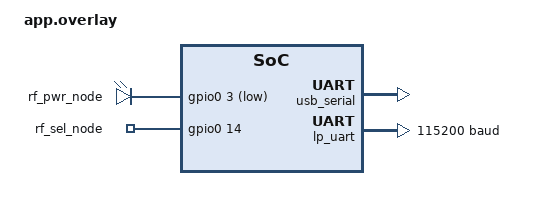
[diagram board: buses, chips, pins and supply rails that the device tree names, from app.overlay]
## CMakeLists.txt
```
# Copyright (c) 2025 Espressif Systems (Shanghai) Co., Ltd.
# SPDX-License-Identifier: Apache-2.0

cmake_minimum_required(VERSION 3.20.0)

list(APPEND EXTRA_CONF_FILE "${CMAKE_CURRENT_SOURCE_DIR}/lp_hp_shared.conf")

set(REMOTE_ZEPHYR_DIR ${CMAKE_CURRENT_BINARY_DIR}/../low_power_sensor_lpcore/zephyr)
set(LP_FULL_BIN ${CMAKE_BINARY_DIR}/../low_power_sensor_lpcore/zephyr/zephyr.bin)
set(LP_STRIPPED_BIN ${CMAKE_BINARY_DIR}/../low_power_sensor_lpcore/zephyr/zephyr_stripped.bin)

# Tell Zephyr to look in this app's directory for snippets
list(APPEND SNIPPET_ROOT ${CMAKE_CURRENT_SOURCE_DIR})

find_package(Zephyr REQUIRED HINTS $ENV{ZEPHYR_BASE})
message(STATUS "${CONFIG_BOARD_TARGET} compile as Master in this sample")
project(low_power_sensor_hpcore)

if(CONFIG_LPS_EXPLICIT_LP_IMAGE_LOADING)
    # This creates a recipe to produce 'zephyr_stripped.bin'
    add_custom_command(
        OUTPUT ${LP_STRIPPED_BIN}
        COMMAND head -c 8192 ${LP_FULL_BIN} > ${LP_STRIPPED_BIN}
        DEPENDS ${LP_FULL_BIN}
        COMMENT ">>> HP BUILD: Stripping LP binary to 8KB <<<"
    )

    # Create a Target to Trigger the Command
    add_custom_target(prepare_lp_binary DEPENDS ${LP_STRIPPED_BIN})

    # This ensures 'zephyr_stripped.bin' exists BEFORE 'src/main.c' or 'src/lp_firmware.S' are compiled.
    add_dependencies(app prepare_lp_binary)
endif()

zephyr_include_directories(include)

target_sources(app PRIVATE src/main.c src/lps_shared.c)

if(CONFIG_LPS_TRANSPORT_WIFI_MQTT)
    target_sources(app PRIVATE src/lps_wifi-mqtt_client.c  src/lps_wifi.c)
elseif(CONFIG_LPS_TRANSPORT_THREAD_MQTTSN)
    target_sources(app PRIVATE src/lps_thread-mqtt-sn_client.c)
endif()

target_sources_ifdef(CONFIG_LPS_DHCP_CLIENT app PRIVATE src/lps_dhcp.c)
target_sources_ifdef(CONFIG_LPS_EXPLICIT_LP_IMAGE_LOADING app PRIVATE src/lp_firmware.S)
```

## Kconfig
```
module = LOW_POWER_SENSOR
module-str = Low Power Sensor
module-help = Low Power Sensor app

source "Kconfig.zephyr"
rsource "Kconfig.lp_hp_shared"

choice LPS_TRANSPORT_AND_TELEMETRY_PROTOCOL
	prompt "LPS Transport and Telemetry Protocol"
	default LPS_TRANSPORT_WIFI_MQTT
	help
	  Select the network transport and messaging protocol combination
	  for the sensor node.

	config LPS_TRANSPORT_WIFI_MQTT
		bool "WiFi + Standard MQTT"
                select NETWORKING
                select NET_SOCKETS
                select NET_UDP
                select NET_IPV4
                select NET_TCP
                select NET_ARP_GRATUITOUS
                select MQTT_LIB
                select MQTT_CLEAN_SESSION
		select WIFI
                select WIFI_ESP32
		help
		  Use standard WiFi for the transport layer and TCP-based 
		  MQTT for telemetry. This is easiest to set up but uses 
		  more battery.

	config LPS_TRANSPORT_THREAD_MQTTSN
		bool "OpenThread + MQTT-SN"
                select NETWORKING
                select NET_SOCKETS
                select NET_UDP
                select NET_IPV6
                select MQTT_SN_LIB
                select MQTT_SN_TRANSPORT_UDP
		select NET_L2_OPENTHREAD
		help
		  Use an 802.15.4 OpenThread mesh for the transport layer 
		  and UDP-based MQTT-SN. Required for hitting the ~20uA 
		  deep-sleep floor.

endchoice

config LPS_EXPLICIT_LP_IMAGE_LOADING
    bool "Load the LP image based on directives within the application"
    default n
    help
        "enable explicit LP image loading"

config LPS_USE_LIGHT_SLEEP
    bool "Use light sleep rather than deep sleep for HP core"
    default n
    help
        "enable HP core light sleep mode"

config LPS_MQTT_BROKER_ADDR
    string "MQTT broker address"
    default ""
    help
        "The address of the MQTT broker".

config LPS_MQTT_BROKER_PORT
    int "MQTT broker port"
    default 1883
    help
        "The UDP port of the MQTT broker".

config LPS_MQTT_BROKER_USERNAME
    string "MQTT broker username"
    default ""
    help
        "The username to connect to MQTT broker".

config LPS_MQTT_BROKER_PASSWORD
    string "MQTT broker password"
    default ""
    help
        "The password to connect to MQTT broker".

config LPS_DHCP_CLIENT
    bool "LPS DHCP client"
    default y
    help
        "enable LPS DHCP client"

config LPS_IP_ADDR
    string "Static IP Address"
    default "192.168.1.100"

config LPS_NETMASK
    string "Static Netmask"
    default "255.255.255.0"

config LPS_GW
    string "Static Gateway"
    default "192.168.1.1"
```

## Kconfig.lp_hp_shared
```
config LPS_HPCORE_ALWAYS_STAY_AWAKE
    bool "Don't put the HP core to sleep (for debugging)"
    default n
    help
        "enable HP core don't sleep"

config LPS_TEMP_CHANGE_PUBLISH_THRESHOLD
    int "LPS temperature change publish threshold"
    default 2
    help
        "LPS temp change publish threshold (10ths of degree C)"

config LPS_HUM_CHANGE_PUBLISH_THRESHOLD
    int "LPS humidity change publish threshold"
    default 5
    help
        "LPS relative humidity change publish threshold (10ths of %)"

config LPS_MAXIMUM_TIME_BETWEEN_PUBLISH_SECONDS
    int "LPS max time between updates"
    default 600
    help
        "LPS maximum seconds between published updates"

config LPS_LOG_LEVEL
    int "LPS Log Level"
    default 0
    help
      Sets the log level for the Low Power Sensor modules.
      0 = OFF
      1 = ERROR
      2 = WARNING
      3 = INFO
      4 = DEBUG
      
```

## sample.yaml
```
sample:
  name: ESP32-C6 LP_CORE Interrupt Sample
tests:
  sample.boards.espressif.ulp.lp_core.low_power_sensor:
    platform_allow:
      - esp32c6_devkitc/esp32c6/hpcore
    tags:
      - samples
    sysbuild: true
```

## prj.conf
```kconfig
# Enable Zephyr Logging
CONFIG_LOG=y

# 0-4  4 is DEBUG
CONFIG_LPS_LOG_LEVEL=4
#CONFIG_LOG_MODE_MINIMAL=y
CONFIG_LOG_MODE_IMMEDIATE=y


# Probably want to configure these things together (the main reason
# to "always stay awake" is so that the shell doesn't disappear).
#CONFIG_LPS_HPCORE_ALWAYS_STAY_AWAKE=y
#CONFIG_NET_SHELL=y
#CONFIG_NET_L2_WIFI_SHELL=n
#CONFIG_OPENTHREAD_SHELL=y
#CONFIG_SETTINGS_SHELL=y


CONFIG_ESP32_ULP_COPROC_ENABLED=y
CONFIG_ESP32_ULP_LP_CORE_WAKEUP_SOURCE_LP_TIMER=y
CONFIG_ESP32_ULP_LP_CORE_LP_TIMER_SLEEP_DURATION_US=30000000

CONFIG_POWEROFF=y
CONFIG_HWINFO=y
CONFIG_MBOX=y

#CONFIG_LPS_EXPLICIT_LP_IMAGE_LOADING=y

CONFIG_REBOOT=y

# --- Memory Tuning (Networking requires more RAM) ---
CONFIG_HEAP_MEM_POOL_SIZE=81920
CONFIG_MAIN_STACK_SIZE=8192
CONFIG_SYSTEM_WORKQUEUE_STACK_SIZE=4096
```

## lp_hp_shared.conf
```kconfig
CONFIG_LPS_TEMP_CHANGE_PUBLISH_THRESHOLD=2
CONFIG_LPS_HUM_CHANGE_PUBLISH_THRESHOLD=5
CONFIG_LPS_MAXIMUM_TIME_BETWEEN_PUBLISH_SECONDS=600
```

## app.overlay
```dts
/*
 * Copyright (c) 2025 Espressif Systems (Shanghai) Co., Ltd.
 *
 * SPDX-License-Identifier: Apache-2.0
 */

/ {
	chosen {
		zephyr,ipc_shm = &ipc_shm;
		zephyr,ipc = &mbox0;
		zephyr,console = &usb_serial;
		zephyr,shell-uart = &usb_serial;                
	};

        mbox_consumer {
               compatible = "vnd,mbox-consumer";
               mboxes = <&mbox0 0>, <&mbox0 1>;
	       mbox-names = "tx", "rx";
        };

        aliases {
                rf-pwr = &rf_pwr_node;
                rf-sel = &rf_sel_node;
        };

        rf_control {
                compatible = "gpio-leds"; 
        
                rf_pwr_node: rf_pwr {
                     /* Active LOW: Setting this to 'active' in
                        C will drive the pin to 0V */
                     gpios = <&gpio0 3 GPIO_ACTIVE_LOW>;
                };
        
                rf_sel_node: rf_sel {
                     /* Active HIGH: Setting this to 'active' in C
                        will drive the pin to 3.3V */
                     gpios = <&gpio0 14 GPIO_ACTIVE_HIGH>;
                };
        };
};

&usb_serial {
	status = "okay";
};

/* Disable this for production, because it consumes about 100uA */
&lp_uart {
	status = "okay";
        current-speed = <115200>;
};
```

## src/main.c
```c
/*
 * main() routine for the high performance core image.
 *
 * Copyright (c) 2025 Espressif Systems (Shanghai) Co., Ltd.
 *
 * SPDX-License-Identifier: Apache-2.0
 */

#include <stdio.h>
#include <zephyr/kernel.h>
#include <zephyr/drivers/gpio.h>
#include <zephyr/drivers/hwinfo.h>
#include <zephyr/drivers/mbox.h>
#include <zephyr/sys/poweroff.h>
#include <zephyr/logging/log.h>
#include <zephyr/devicetree.h>

#include <esp_attr.h>

#include <esp_sleep.h>
#include <ulp_lp_core.h>

#include "shared_data.h"
#include "lps_transport.h"

LOG_MODULE_REGISTER(lps_hp, CONFIG_LPS_LOG_LEVEL);

#if defined(CONFIG_LPS_EXPLICIT_LP_IMAGE_LOADING)    
extern const uint8_t ulp_lp_core_app_start[];
extern const uint8_t ulp_lp_core_app_end[];
#endif // CONFIG_LPS_EXPLICIT_LP_IMAGE_LOADING

static RTC_DATA_ATTR uint32_t hp_wake_count = 0;
static RTC_DATA_ATTR bool first_boot=true;

const struct mbox_dt_spec rx_channel =
    MBOX_DT_SPEC_GET(DT_PATH(mbox_consumer), rx);
const struct mbox_dt_spec tx_channel =
    MBOX_DT_SPEC_GET(DT_PATH(mbox_consumer), tx);

#define SHM_NODE DT_CHOSEN(zephyr_ipc_shm)
#define SHM_BASE_ADDR DT_REG_ADDR(SHM_NODE)

/* Fetch the hardware mappings from the devicetree aliases */
static const struct gpio_dt_spec rf_pwr = GPIO_DT_SPEC_GET(DT_ALIAS(rf_pwr), gpios);
static const struct gpio_dt_spec rf_sel = GPIO_DT_SPEC_GET(DT_ALIAS(rf_sel), gpios);

/* Create a direct window into the RTC SRAM so there's no need to copy */
volatile lp_to_hp_shared_data_t *shared_data = 
    (volatile lp_to_hp_shared_data_t *)SHM_BASE_ADDR;

static K_SEM_DEFINE(mbox_sem, 0, 1);


static void callback(const struct device *dev,
                     mbox_channel_id_t channel_id,
                     void *user_data,
                     struct mbox_msg *data)
{
    LOG_DBG("calling callback(channel_id=%d, data=0x%x)", (uint32_t) channel_id, (uint32_t)data);

    lp_to_hp_shared_data_t *incoming = (lp_to_hp_shared_data_t *)data->data;

    /* Drop the power-on phantom interrupt instantly */
    if (incoming->shared_magic != SHARED_DATA_MAGIC_NUMBER) {
        return; 
    }
       
    /* Safely signal the main thread that data is ready */
    k_sem_give(&mbox_sem);
}

static void enable_external_antenna(void)
{
    if (!gpio_is_ready_dt(&rf_pwr) || !gpio_is_ready_dt(&rf_sel)) {
        return;
    }

    /* * Configure pins as outputs and assert them. 
     * Because of our DT flags, ACTIVE here means:
     * GPIO 3  -> driven LOW  (Powers the switch)
     * GPIO 14 -> driven HIGH (Selects U.FL connector)
     */
    gpio_pin_configure_dt(&rf_pwr, GPIO_OUTPUT_ACTIVE);
    gpio_pin_configure_dt(&rf_sel, GPIO_OUTPUT_ACTIVE);
}

#if !defined(CONFIG_LPS_HPCORE_ALWAYS_STAY_AWAKE)
static void disable_external_antenna(void)
{
    /* * De-assert pins before entering deep sleep.
     * INACTIVE here means:
     * GPIO 3 -> driven HIGH (Cuts power to the switch, saving ~100 µA)
     */
    gpio_pin_configure_dt(&rf_pwr, GPIO_OUTPUT_INACTIVE);
    gpio_pin_configure_dt(&rf_sel, GPIO_OUTPUT_INACTIVE);
}
#endif // !CONFIG_LPS_HPCORE_ALWAYS_STAY_AWAKE

int main(void)
{
    uint32_t cause;
    bool successful_publish = PUBLISH_STATUS_PENDING;

#if defined(CONFIG_LPS_HPCORE_ALWAYS_STAY_AWAKE)
    enable_external_antenna();
    
    while (1) {
#else
    // 1. Check wakeup cause
	if (hwinfo_get_reset_cause(&cause) == 0) {
	    if (!(cause & RESET_LOW_POWER_WAKE) && hp_wake_count != 0) {
		LOG_ERR("BOOT: Unexpected reset cause: %08x\n", cause);
	    }
	    hwinfo_clear_reset_cause(); 
	} else {
	    LOG_ERR("BOOT: Could not determine reset cause.\n");
	}
	
	enable_external_antenna();
#endif
	
    if (!lps_transport_init()) {
	LOG_ERR("lps_transport_init() returned false");
    }

#if defined(CONFIG_LPS_HPCORE_ALWAYS_STAY_AWAKE)
    if (true) {
#else
    if (cause & RESET_LOW_POWER_WAKE || hp_wake_count == 0) {	
#endif
        LOG_DBG(">>> HP WAKE: Woken by LP Core! <<<");

	if (mbox_register_callback_dt(&rx_channel, callback, NULL)) {
	    LOG_ERR("mbox_register_callback() error");
	    return 0;
	}
	else {
	    LOG_DBG("registered mbox callback");
	}

	if (mbox_set_enabled_dt(&rx_channel, 1)) {
	    LOG_ERR("mbox_set_enable() error");
	    return 0;
	}
	else {
	    LOG_DBG("enabled mbox");
	}

	/* First boot requires a bit of a delay to give LP core time to do its initial read */
	if (hp_wake_count == 0) {
	    while (shared_data->shared_magic != SHARED_DATA_MAGIC_NUMBER) {
		k_msleep(50);
	    }
	}
	
#if defined(CONFIG_LPS_HPCORE_ALWAYS_STAY_AWAKE)	
	LOG_DBG("Waiting for message from LP core to appear in mbox");	
        /* Thread sleeps natively until the callback gives the semaphore
	   we don't bother with the semaphore in the production mode, because
	   being woken from deep sleep itself serves as the "doorbell" then. */
        k_sem_take(&mbox_sem, K_FOREVER);
#endif // CONFIG_LPS_HPCORE_ALWAYS_STAY_AWAKE

	LOG_DBG("Message value received:" \
	       " .lp_wake_count=%d" \
	       " .hp_wake_count=%d" \
	       " .temp_c_x10=%d" \
	       " .rh_x10=%d", \
	       shared_data->lp_wake_count, \
	       shared_data->hp_wake_count, \
	       shared_data->temp_c_x10, \
	       shared_data->rh_x10);
	
	successful_publish = lps_transport_send_update(shared_data);

	LOG_DBG("successful_publish = %s",
		successful_publish ? "true" : "false");
    }

    else if (first_boot)
    {	
	LOG_DBG(">>> HP BOOT: Cold start.");
#if defined(CONFIG_LPS_EXPLICIT_LP_IMAGE_LOADING)    	
        LOG_DBG("   Loading LP firmware... ");

        /* Load LP firmware into RTC RAM */
        ulp_lp_core_load_binary(ulp_lp_core_app_start,
				(ulp_lp_core_app_end - ulp_lp_core_app_start));

	ulp_lp_core_cfg_t cfg = {
            .wakeup_source = ULP_LP_CORE_WAKEUP_SOURCE_HP_CPU,
        };
	
        /* Start the LP Core */
        ulp_lp_core_run(&cfg);

	first_boot=false;
	
	LOG_DBG(" Done loading firmware. LP core started.");
#endif // CONFIG_LPS_EXPLICIT_LP_IMAGE_LOADING
    }

    LOG_DBG(">>> HP SLEEP: Entering Deep Sleep... %d <<<", hp_wake_count);
    
    hp_wake_count++;

#if defined(CONFIG_LOG)    
    // Allow UART to flush before cutting power (make sure it's long enough)
    k_msleep(1500); 
#endif // CONFIG_LOG

    // Enable ULP wakeup (keeps LP core powered on!)
    esp_sleep_enable_ulp_wakeup();
    
    /* * Disable the MBOX interrupt to prevent race conditions. 
     * If the LP core fires a new message while we are shutting down, 
     * the CPU will ignore it, leaving the hardware wake flag perfectly 
     * intact for the deep sleep wake controller to see.
     */
    if (mbox_set_enabled_dt(&rx_channel, 0)) {
	LOG_ERR("Failed to disable mbox interrupt");
    }

    if (!lps_transport_shutdown()) {
	LOG_ERR("lps_transport_shutdown() returned false");
    }

#if !defined(CONFIG_LPS_HPCORE_ALWAYS_STAY_AWAKE)
    disable_external_antenna();
#endif // !CONFIG_LPS_HPCORE_ALWAYS_STAY_AWAKE
    
    /* Write the receipt indicating success or failure of the event publish directly to
       the LP core's RTC memory. */
    if (shared_data->most_recent_publish_status_p != NULL) {
	*(shared_data->most_recent_publish_status_p) =
	    successful_publish ? PUBLISH_STATUS_SUCCESS : PUBLISH_STATUS_FAILURE;
	LOG_DBG("Wrote receipt %d to LP core.",
		*(shared_data->most_recent_publish_status_p));
    }
       
    // Power down or put the HP core to sleep
#if !defined(CONFIG_LPS_HPCORE_ALWAYS_STAY_AWAKE)
    esp_deep_sleep_start();
#endif // !CONFIG_LPS_HPCORE_ALWAYS_STAY_AWAKE

#if defined(CONFIG_LPS_HPCORE_ALWAYS_STAY_AWAKE)
    /* Drain any extra spurious signals that stacked up to prevent double-execution */
    k_sem_reset(&mbox_sem);

    } // while (1) infinite loop
#endif    

}
```

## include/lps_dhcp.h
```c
#ifndef LPS_MICRO_DHCP_H
#define LPS_MICRO_DHCP_H

/**
 * @brief Executes a synchronous, blocking DHCP DORA sequence
 *        over raw UDP sockets.
 * @param ip Parsed IP address assigned by the router.
 * @param netmask Parsed Subnet Mask.
 * @param gw Parsed Router/Gateway address.
 * @return 0 on success, negative error code on timeout or failure.
 */
int lps_dhcp_run(struct in_addr *ip,
		       struct in_addr *netmask,
		       struct in_addr *gw);

#endif /* LPS_MICRO_DHCP_H */
```

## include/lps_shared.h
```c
#include <zephyr/kernel.h>
#include <zephyr/net/socket.h>
#include "shared_data.h"

extern void get_device_id(char *id_buffer, size_t buffer_size);
extern void get_json_message(char *json_message_buffer,
			     size_t buffer_size,
			     char* device_id,
			     volatile lp_to_hp_shared_data_t *data);
extern void get_topic(char *topic_buffer,
		      size_t topic_buffer_size,
		      char *device_id);
```

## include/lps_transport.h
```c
extern bool lps_transport_send_update(volatile lp_to_hp_shared_data_t *);
extern bool lps_transport_init();
extern bool lps_transport_shutdown();
```

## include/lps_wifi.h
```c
#ifndef LPS_WIFI_H
#define LPS_WIFI_H

#include <stdbool.h>

/**
 * @brief Wakes the Wi-Fi radio and establishes a connection to the AP.
 * Applies either a cached "Fake Static" DHCP lease or initiates 
 * a full DHCP DORA sequence if the cache is empty/invalid.
 */
bool lps_wifi_prepare_connection(void);

/**
 * @brief Gracefully tears down the Wi-Fi connection.
 * Sends an 802.11 Deauth frame to the AP to clear the router's 
 * state table and prevent "Ghost Client" association rejections.
 */
void lps_wifi_teardown_connection(void);

/**
 * @brief Invalidates the RTC DHCP cache.
 * Used as a reactive fallback when network routing fails, forcing 
 * a full, clean DHCP request on the next boot cycle.
 */
void lps_wifi_invalidate_dhcp_cache(void);

#endif /* LPS_WIFI_H */
```

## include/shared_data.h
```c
#ifndef SHARED_DATA_H
#define SHARED_DATA_H

#include <stdint.h>
#include <stdbool.h>

#define SHARED_DATA_MAGIC_NUMBER 0x08675309

typedef enum {
    PUBLISH_STATUS_PENDING,
    PUBLISH_STATUS_SUCCESS,
    PUBLISH_STATUS_FAILURE
} publish_status_t;

typedef struct __attribute__((aligned(4))) {
    uint32_t shared_magic;
    uint32_t lp_wake_count;
    uint32_t hp_wake_count;
    int16_t  temp_c_x10; // e.g., 218 = 21.8 C
    uint16_t rh_x10;     // e.g., 452 = 45.2 % RH
    volatile publish_status_t *most_recent_publish_status_p;
} lp_to_hp_shared_data_t;
    
#endif
```

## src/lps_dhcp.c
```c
#include <zephyr/kernel.h>
#include <zephyr/net/socket.h>
#include <zephyr/net/net_if.h>
#include <zephyr/net/net_pkt.h>
#include <zephyr/net/ethernet.h>
#include <zephyr/random/random.h>
#include <string.h>
#include <errno.h>
#include <zephyr/logging/log.h>
#include "lps_dhcp.h"

LOG_MODULE_DECLARE(lps_hp, CONFIG_LPS_LOG_LEVEL);

#define DHCP_CLIENT_PORT 68
#define DHCP_SERVER_PORT 67
#define DHCP_MAGIC_COOKIE 0x63825363
#define DHCP_TIMEOUT_MS 6000

#define DHCP_DISCOVER 1
#define DHCP_OFFER    2
#define DHCP_REQUEST  3
#define DHCP_ACK      5

#define OPT_SUBNET_MASK 1
#define OPT_ROUTER      3
#define OPT_REQ_IP      50
#define OPT_MSG_TYPE    53
#define OPT_SERVER_ID   54
#define OPT_PARAM_REQ   55
#define OPT_END         255

struct __attribute__((packed)) eth_hdr {
    uint8_t  dst[6];
    uint8_t  src[6];
    uint16_t type;
};

struct __attribute__((packed)) ip_hdr {
    uint8_t  vhl;
    uint8_t  tos;
    uint16_t len;
    uint16_t id;
    uint16_t off;
    uint8_t  ttl;
    uint8_t  proto;
    uint16_t csum;
    uint32_t src;
    uint32_t dst;
};

struct __attribute__((packed)) udp_hdr {
    uint16_t src;
    uint16_t dst;
    uint16_t len;
    uint16_t csum;
};

struct __attribute__((packed)) dhcp_msg {
    uint8_t  op;
    uint8_t  htype;
    uint8_t  hlen;
    uint8_t  hops;
    uint32_t xid;
    uint16_t secs;
    uint16_t flags;
    uint32_t ciaddr;
    uint32_t yiaddr;
    uint32_t siaddr;
    uint32_t giaddr;
    uint8_t  chaddr[16];
    uint8_t  sname[64];
    uint8_t  file[128];
    uint32_t magic_cookie;
    uint8_t  options[64]; 
};

struct __attribute__((packed)) raw_dhcp_packet {
    struct eth_hdr  eth;
    struct ip_hdr   ip;
    struct udp_hdr  udp;
    struct dhcp_msg dhcp;
};

static uint16_t calc_ip_csum(const uint8_t *buf, size_t len) {
    uint32_t sum = 0;
    for (size_t i = 0; i < len; i += 2) {
	sum += (buf[i] << 8) | buf[i + 1];
    }
    while (sum >> 16) {
	sum = (sum & 0xffff) + (sum >> 16);
    }
    return htons((uint16_t)~sum);
}

static int push_raw_frame(struct net_if *iface, struct raw_dhcp_packet *tx_pkt) {
    struct net_pkt *pkt =
	net_pkt_alloc_with_buffer(iface, sizeof(*tx_pkt),
				  AF_UNSPEC, 0, K_NO_WAIT);
    if (!pkt) {
	return -1;
    }

    if (net_pkt_write(pkt, tx_pkt, sizeof(*tx_pkt)) < 0) {
        net_pkt_unref(pkt);
        return -1;
    }
    net_pkt_cursor_init(pkt);

    const struct device *dev = net_if_get_device(iface);
    const struct ethernet_api *api = (const struct ethernet_api *)dev->api;

    int ret = api->send(dev, pkt);
    
    // We ONLY unref it if the hardware rejected the handoff entirely.
    if (ret < 0) {
        net_pkt_unref(pkt); 
    }
    return ret;
}

int lps_dhcp_run(struct in_addr *ip,
		 struct in_addr *netmask,
		 struct in_addr *gw)
{
    int sock = -1;
    int ret = -1; 
    struct net_if *iface = net_if_get_default();
    struct net_linkaddr *mac = net_if_get_link_addr(iface);
    uint32_t server_id = 0;
    uint32_t transaction_id = sys_rand32_get() ^ k_cycle_get_32();
    
    struct raw_dhcp_packet tx_pkt;
    struct dhcp_msg rx_dhcp; 

    if (mac->len != 6) return -1;

    // Setup recieve hook
    struct in_addr dummy_ip, dummy_mask;
    net_addr_pton(AF_INET, "0.0.0.0", &dummy_mask); 
    
    if (ip->s_addr != 0) {
        dummy_ip.s_addr = ip->s_addr;
        LOG_DBG("Listening for Unicast replies on expired IP...");
    } else {
        net_addr_pton(AF_INET, "169.254.1.1", &dummy_ip);
        LOG_DBG("Listening for Broadcast replies on dummy IP...");
    }
    
    net_if_ipv4_addr_add(iface, &dummy_ip, NET_ADDR_MANUAL, 0);
    net_if_ipv4_set_netmask_by_addr(iface, &dummy_ip, &dummy_mask);

    LOG_DBG("Opening UDP socket...");
    sock = zsock_socket(AF_INET, SOCK_DGRAM, IPPROTO_UDP);
    if (sock < 0) {
        LOG_DBG("DHCP ERROR: zsock_socket failed. errno: %d", errno);
        goto cleanup;
    }

    struct sockaddr_in bind_addr = {0};
    bind_addr.sin_family = AF_INET;
    bind_addr.sin_port = htons(DHCP_CLIENT_PORT);
    bind_addr.sin_addr.s_addr = INADDR_ANY; 
    
    LOG_DBG("Binding socket to port 68...");
    if (zsock_bind(sock,
		   (struct sockaddr *)&bind_addr,
		   sizeof(bind_addr)) < 0) {
        LOG_DBG("DHCP ERROR: zsock_bind failed. errno: %d", errno);
        goto cleanup;
    }

    // Set up the poll file descriptor structure
    struct zsock_pollfd poll_fd = {
        .fd = sock,
        .events = ZSOCK_POLLIN,
    };

    // Assemble the monolithic frame
    memset(&tx_pkt, 0, sizeof(tx_pkt));
    memset(tx_pkt.eth.dst, 0xFF, 6);
    memcpy(tx_pkt.eth.src, mac->addr, 6);
    tx_pkt.eth.type = htons(0x0800); 

    tx_pkt.ip.vhl = 0x45; 
    tx_pkt.ip.tos = 0;
    tx_pkt.ip.len = htons(sizeof(struct ip_hdr) +
			  sizeof(struct udp_hdr) +
			  sizeof(struct dhcp_msg));
    tx_pkt.ip.id = htons(1);
    tx_pkt.ip.ttl = 64;
    tx_pkt.ip.proto = 17; 
    tx_pkt.ip.src = 0;    
    tx_pkt.ip.dst = 0xFFFFFFFF; 
    tx_pkt.ip.csum = calc_ip_csum((uint8_t *)&tx_pkt.ip,
				  sizeof(struct ip_hdr));

    tx_pkt.udp.src = htons(DHCP_CLIENT_PORT);
    tx_pkt.udp.dst = htons(DHCP_SERVER_PORT);
    tx_pkt.udp.len = htons(sizeof(struct udp_hdr) +
			   sizeof(struct dhcp_msg));

    tx_pkt.dhcp.op = 1; 
    tx_pkt.dhcp.htype = 1; 
    tx_pkt.dhcp.hlen = 6;
    tx_pkt.dhcp.xid = transaction_id;
    tx_pkt.dhcp.flags = htons(0x8000); 
    memcpy(tx_pkt.dhcp.chaddr, mac->addr, 6);
    tx_pkt.dhcp.magic_cookie = htonl(DHCP_MAGIC_COOKIE);

    uint8_t *opt = tx_pkt.dhcp.options;
    *opt++ = OPT_MSG_TYPE; *opt++ = 1;
    *opt++ = DHCP_DISCOVER;
    *opt++ = OPT_PARAM_REQ; *opt++ = 2;
    *opt++ = OPT_SUBNET_MASK;
    *opt++ = OPT_ROUTER; 
    *opt++ = OPT_END;

    LOG_DBG("Executing Direct Hardware Handoff (DISCOVER)...");
    if (push_raw_frame(iface, &tx_pkt) < 0) {
        LOG_DBG("DHCP ERROR: push_raw_frame failed.");
        goto cleanup;
    }

    // Wait for offer
    bool offer_received = false;
    LOG_DBG("Waiting up to %dms for DHCP OFFER...", DHCP_TIMEOUT_MS);
    while (!offer_received) {
	 // Wait strictly for DHCP_TIMEOUT_MS ms
        int poll_res = zsock_poll(&poll_fd, 1, DHCP_TIMEOUT_MS);
        
        if (poll_res == 0) {
            LOG_DBG("DHCP WARNING: Poll timeout waiting for OFFER.");
            goto cleanup;
        } else if (poll_res < 0) {
            LOG_DBG("DHCP ERROR: zsock_poll failed. errno: %d", errno);
            goto cleanup;
        }

        // We use ZSOCK_MSG_DONTWAIT to guarantee recvfrom never blocks
        if (zsock_recvfrom(sock, &rx_dhcp, sizeof(rx_dhcp),
			   ZSOCK_MSG_DONTWAIT, NULL, NULL) < 0) {
            continue; // Could be a spurious wake, just loop back to poll
        }

        if (rx_dhcp.op == 2 && rx_dhcp.xid == transaction_id) {
            opt = rx_dhcp.options;
            while (*opt != OPT_END && opt <
		   rx_dhcp.options + sizeof(rx_dhcp.options)) {
                if (*opt == 0) {
		    opt++;
		    continue;
		} 
                uint8_t tag = *opt++; uint8_t len = *opt++;
                if (tag == OPT_MSG_TYPE && *opt == DHCP_OFFER) {
		    offer_received = true;
		}
                if (tag == OPT_SERVER_ID) {
		    memcpy(&server_id, opt, 4);
		}
                opt += len;
            }
        }
    }

    // Send DHCP request
    memset(tx_pkt.dhcp.options, 0, sizeof(tx_pkt.dhcp.options));
    opt = tx_pkt.dhcp.options;
    *opt++ = OPT_MSG_TYPE;
    *opt++ = 1;
    *opt++ = DHCP_REQUEST;
    *opt++ = OPT_REQ_IP;
    *opt++ = 4;
    memcpy(opt, &rx_dhcp.yiaddr, 4);
    opt += 4;
    *opt++ = OPT_SERVER_ID;*opt++ = 4;
    memcpy(opt, &server_id, 4);
    opt += 4;
    *opt++ = OPT_END;

    tx_pkt.ip.csum = 0;
    tx_pkt.ip.csum = calc_ip_csum((uint8_t *)&tx_pkt.ip,
				  sizeof(struct ip_hdr));

    LOG_DBG("Executing Direct Hardware Handoff (REQUEST)...");
    if (push_raw_frame(iface, &tx_pkt) < 0) {
        LOG_DBG("DHCP ERROR: push_raw_frame (REQUEST) failed.");
        goto cleanup;
    }

    // Wait for ACK
    LOG_DBG("Waiting for DHCP ACK...");
    while (1) {
        int poll_res = zsock_poll(&poll_fd, 1, 3000); 
        
        if (poll_res <= 0) {
            LOG_DBG("DHCP WARNING: Poll timeout/error waiting for ACK.");
            goto cleanup;
        }

        if (zsock_recvfrom(sock, &rx_dhcp, sizeof(rx_dhcp),
			   ZSOCK_MSG_DONTWAIT, NULL, NULL) < 0) {
            continue;
        }

        if (rx_dhcp.op == 2 && rx_dhcp.xid == transaction_id) {
            ip->s_addr = rx_dhcp.yiaddr;
            
            opt = rx_dhcp.options;
            while (*opt != OPT_END && opt <
		   rx_dhcp.options + sizeof(rx_dhcp.options)) {
                if (*opt == 0) { opt++; continue; }
                uint8_t tag = *opt++;
		uint8_t len = *opt++;
                if (tag == OPT_MSG_TYPE && *opt == DHCP_ACK) {
		    ret = 0;
		}
                if (tag == OPT_SUBNET_MASK) {
		    memcpy(&netmask->s_addr, opt, 4);
		}
                if (tag == OPT_ROUTER) {
		    memcpy(&gw->s_addr, opt, 4);
		}
                opt += len;
            }
            if (ret == 0) {
		break;
	    }
        }
    }

cleanup:
    if (sock >= 0) {
	zsock_close(sock);
    }
    net_if_ipv4_addr_rm(iface, &dummy_ip);
    return ret;
}
```

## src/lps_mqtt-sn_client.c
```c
#include <zephyr/kernel.h>
#include <zephyr/logging/log.h>
#include <zephyr/settings/settings.h>
#include <zephyr/net/net_if.h>
#include <zephyr/net/socket.h>
#include <zephyr/net/mqtt_sn.h>

#include <zephyr/net/openthread.h>
#include <zephyr/sys/util.h> 
#include <openthread/thread.h>
#include <openthread/ip6.h>

#include "lps_shared.h"


LOG_MODULE_DECLARE(lps_hp, CONFIG_LPS_LOG_LEVEL);

/* Global MQTT-SN Buffers and Structs */
static uint8_t mqtt_sn_tx_buf[512];
static uint8_t mqtt_sn_rx_buf[512];
static struct mqtt_sn_client sn_client;
static struct mqtt_sn_transport_udp sn_transport; /* Zephyr 4.4 Transport Wrapper */

static volatile bool is_mqtt_sn_connected = false;
volatile lp_to_hp_shared_data_t *sensor_data;

/* Zephyr 4.4 strictly requires an event callback */
static void mqtt_sn_evt_cb(struct mqtt_sn_client *client, const struct mqtt_sn_evt *evt)
{
    switch (evt->type) {
        case MQTT_SN_EVT_CONNECTED:
            LOG_DBG("MQTT-SN Event: CONNECTED");
	    is_mqtt_sn_connected = true;
            break;
        case MQTT_SN_EVT_DISCONNECTED:
            LOG_DBG("MQTT-SN Event: DISCONNECTED");
	    is_mqtt_sn_connected = false;
            break;
        default:
            break;
    }
}


/* * Blocks until the OpenThread stack successfully attaches to the mesh.
 * Returns true if attached, false if it times out.
 */
static bool wait_for_thread_mesh(uint32_t timeout_ms) {
    otInstance *instance = openthread_get_default_instance();
    if (!instance) {
        LOG_ERR("OpenThread instance not initialized.");
        return false;
    }

    LOG_DBG("Waiting for OpenThread mesh attachment...");
    
    uint32_t elapsed = 0;
    while (elapsed < timeout_ms) {
        otDeviceRole role = otThreadGetDeviceRole(instance);
        
        /* A Sleepy End Device will attach as a CHILD */
        if (role == OT_DEVICE_ROLE_CHILD || 
            role == OT_DEVICE_ROLE_ROUTER || 
            role == OT_DEVICE_ROLE_LEADER) {
            LOG_DBG("Attached to mesh! Role: %d", role);
            return true;
        }
        
        k_msleep(100);
        elapsed += 100;
    }
    
    LOG_DBG("Timeout waiting for mesh attachment.");
    return false;
}


static void pump_mqtt_sn_socket(struct mqtt_sn_transport_udp *transport, 
                                struct mqtt_sn_client *client, 
                                int timeout_ms) 
{
    struct zsock_pollfd fds[1] = {
        { .fd = transport->sock, .events = ZSOCK_POLLIN, .revents = 0 }
    };

    int time_left = timeout_ms;
    while (time_left > 0) {
        if (zsock_poll(fds, 1, 100) > 0) {
            mqtt_sn_input(client);
        }
        time_left -= 100;
    }
}

bool lps_send_update(volatile lp_to_hp_shared_data_t *sensor_data) 
{
    static bool successful_publish = false;
    /* 1. Persistent OS Context */
    static bool is_net_initialized = false;
    
    /* 2. Persistent Payload Memory (Prevents the (null) pointer bug) */
    char device_id[20];
    char payload[128];
    char topic[64];
    
    static struct mqtt_sn_data pub_data;
    static struct mqtt_sn_data pub_topic;
    
    get_device_id(device_id, sizeof(device_id));
    get_json_message(payload, sizeof(payload), device_id, sensor_data);
    get_topic(topic, sizeof(topic), device_id);
    
    pub_data.data = (uint8_t *)payload;
    pub_data.size = strlen(payload);

    pub_topic.data = (uint8_t *)topic;
    pub_topic.size = strlen(topic);

    /* 3. STRICTLY One-Time Initialization */
    if (!is_net_initialized) {
        /* 3. OS Initialization & State Flushing */
	static bool is_socket_bound = false;

	if (!is_socket_bound) {
	    LOG_DBG("--- Binding UDP Socket ---");
	    struct sockaddr_in6 mcast_addr = {0};
	    mcast_addr.sin6_family = AF_INET6;
	    mcast_addr.sin6_port = htons(0); 
	    zsock_inet_pton(AF_INET6, "ff03::1", &mcast_addr.sin6_addr);

	    if (mqtt_sn_transport_udp_init(&sn_transport, (struct sockaddr *)&mcast_addr, sizeof(mcast_addr)) < 0) {
		return false;
	    }
	    is_socket_bound = true;
	}

	/* --- THE FIX: Always re-init the client to flush Zephyr's dirty TX queues --- */
	LOG_DBG("Flushing MQTT-SN Client state...");
	struct mqtt_sn_data client_id = MQTT_SN_DATA_STRING_LITERAL("esp32c6_sensor");
	if (mqtt_sn_client_init(&sn_client, &client_id, &sn_transport.tp, mqtt_sn_evt_cb, 
				mqtt_sn_tx_buf, sizeof(mqtt_sn_tx_buf), 
				mqtt_sn_rx_buf, sizeof(mqtt_sn_rx_buf)) < 0) {
	    return false;
	}

	struct sockaddr_in6 gw_addr = {0};
	gw_addr.sin6_family = AF_INET6;
	gw_addr.sin6_port = htons(CONFIG_LPS_MQTT_BROKER_PORT);
	zsock_inet_pton(AF_INET6, CONFIG_LPS_MQTT_BROKER_ADDR, &gw_addr.sin6_addr);
	
	struct mqtt_sn_data gw_addr_data = { .data = (const uint8_t *)&gw_addr, .size = sizeof(gw_addr) };
	mqtt_sn_add_gw(&sn_client, 1, gw_addr_data);
	
        is_net_initialized = true;
    }

    LOG_DBG("Waking up. Waiting for Thread Mesh...");
    wait_for_thread_mesh(30000);
    
    /* 4. Speed up MAC layer for the transaction */
    otInstance *ot = openthread_get_default_instance();
    if (ot != NULL) otLinkSetPollPeriod(ot, 100);

    /* 5. Connect */
    LOG_DBG("--- Connecting ---");
    int retries = 3;
    is_mqtt_sn_connected = false;

    while (retries > 0 && !is_mqtt_sn_connected) {
        LOG_DBG("Sending MQTT-SN CONNECT (Attempt %d)...", 4 - retries);
        
        int err = mqtt_sn_connect(&sn_client, false, true);
        if (err != 0) {
            LOG_WRN("Connect API returned %d. Mesh routing likely converging. Waiting...", err);
            k_msleep(1000); /* Give Thread 1 second to settle its IPv6 routes */
            retries--;
            continue;
        }

        /* Pump the socket for up to 3 seconds waiting for the CONNACK */
        pump_mqtt_sn_socket(&sn_transport, &sn_client, 3000);

        if (!is_mqtt_sn_connected) {
            LOG_WRN("Timeout waiting for CONNACK. Retrying...");
            retries--;
        }
    }

    if (!is_mqtt_sn_connected) {
        LOG_ERR("Failed to connect after retries.");
        if (ot != NULL) otLinkSetPollPeriod(ot, 0);
        return false;
    }


    /* 6. Register & Publish with QoS 1 Handshake Confirmation */
    LOG_DBG("--- Registering & Publishing (QoS 1) ---");
    
    /* Upgrade to QoS 1 so the library tracks the transaction and mandates a PUBACK */
    if (mqtt_sn_publish(&sn_client, MQTT_SN_QOS_1, &pub_topic, false, &pub_data) != 0) {
        LOG_ERR("Publish API failed.");
        successful_publish = false;
    } else {
        /* Poll the socket and wait for the internal tracking queue to empty,
           proving Zephyr successfully intercepted and processed the incoming PUBACK */
        int ack_timeout_ms = 20000;
        successful_publish = false;

        while (ack_timeout_ms > 0) {
            /* Feed incoming datagrams to the state machine */
            pump_mqtt_sn_socket(&sn_transport, &sn_client, 250);
            
            /* Zephyr tracks pending QoS 1/2 acknowledgments in the client.publish list */
            if (sys_slist_is_empty(&sn_client.publish)) {
                LOG_DBG("PUBACK received! Publish safely confirmed by Gateway.");
                successful_publish = true;
                break;
            }
            ack_timeout_ms -= 250;
        }

        if (!successful_publish) {
            LOG_ERR("Publish transaction failed: Timeout waiting for Gateway PUBACK.");
        }
    }

    /* 7. Clean Disconnect */
    LOG_DBG("--- Disconnecting ---");
    mqtt_sn_disconnect(&sn_client);
    
    /* Give the radio 500ms to physically transmit the DISCONNECT packet */
    pump_mqtt_sn_socket(&sn_transport, &sn_client, 500);

    /* Drop MAC poll to save power */
    if (ot != NULL) {
        otLinkSetPollPeriod(ot, 0);
    }

    return successful_publish;
}
```

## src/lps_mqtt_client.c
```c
#include <zephyr/net/mqtt.h>
#include <zephyr/net/socket.h>
#include <zephyr/random/random.h>
#include <zephyr/kernel.h>
#include <zephyr/logging/log.h>
#include "shared_data.h"
#include "lps_wifi.h"

LOG_MODULE_DECLARE(lps_hp, CONFIG_LPS_LOG_LEVEL);

#define BROKER_ADDR CONFIG_LPS_MQTT_BROKER_ADDR 
#define BROKER_PORT CONFIG_LPS_MQTT_BROKER_PORT

static uint8_t rx_buffer[128];
static uint8_t tx_buffer[128];
static struct mqtt_client client_ctx;
static struct sockaddr_in broker;
static struct zsock_pollfd fds[1];

lp_to_hp_shared_data_t *sensor_data;

// Event notification semaphores
static K_SEM_DEFINE(mqtt_conn_sem, 0, 1);
static K_SEM_DEFINE(mqtt_pub_sem, 0, 1);

static void mqtt_evt_handler(struct mqtt_client *const client,
                             const struct mqtt_evt *evt)
{
    switch (evt->type) {
    case MQTT_EVT_CONNACK:
        if (evt->param.connack.return_code == MQTT_CONNECTION_ACCEPTED) {
            LOG_DBG("MQTT connected!");
            k_sem_give(&mqtt_conn_sem);
        } else {
            LOG_DBG("MQTT connection refused: %d", evt->param.connack.return_code);
        }
        break;
    case MQTT_EVT_PUBACK:
        LOG_DBG("MQTT PUBACK received! Data is safely on the broker.");
        k_sem_give(&mqtt_pub_sem);
        break;
    case MQTT_EVT_DISCONNECT:
        LOG_DBG("MQTT disconnected.");
        break;
    default:
        break;
    }
}

static void get_device_id(char *id_buffer, size_t buffer_size)
{
    struct net_if *iface = net_if_get_default();
    struct net_linkaddr *link_addr = net_if_get_link_addr(iface);

    if (link_addr && link_addr->len == 6) {
        snprintf(id_buffer, buffer_size, "lps_%02x%02x%02x",
                 link_addr->addr[3], link_addr->addr[4], link_addr->addr[5]);
    } else {
        snprintf(id_buffer, buffer_size, "unknown_device");
    }
}

static int publish_sensor_data(int32_t seq, int16_t temp_c_x10, uint16_t rh_x10, uint16_t msg_id, uint8_t is_dup)
{
    char payload[128];
    char device_id[20];
    
    get_device_id(device_id, sizeof(device_id));
    
    snprintf(payload, sizeof(payload), 
             "{\"id\": \"%s\", \"seq\": %d, \"temperature\": %d.%d, \"humidity\": %d.%d}", 
             device_id,
	     seq,
             temp_c_x10 / 10, abs(temp_c_x10 % 10), 
             rh_x10 / 10, abs(rh_x10 % 10));

    char topic[64];
    snprintf(topic, sizeof(topic), "sensors/%s/env", device_id);
    LOG_DBG("publishing to topic %s", topic);
    
    struct mqtt_publish_param param;

    param.message.topic.qos = MQTT_QOS_1_AT_LEAST_ONCE;
    param.message.topic.topic.utf8 = (uint8_t *)topic;
    param.message.topic.topic.size = strlen(topic);
    param.message.payload.data = payload;
    param.message.payload.len = strlen(payload);

    // Use the stable ID and set the Duplicate flag
    param.message_id = msg_id;
    param.dup_flag = is_dup;
    param.retain_flag = 0;

    return mqtt_publish(&client_ctx, &param);
}

static bool send_mqtt_update(void)
{
    static struct mqtt_utf8 password;
    static struct mqtt_utf8 username;
    bool successful_publish = false;

    // Generate a single 16-bit Message ID for this entire wake cycle
    uint16_t current_msg_id = sys_rand32_get() & 0xFFFF;
    
    // Master Session Loop. 
    // If ANY step of the MQTT flow fails, we tear down the TCP socket, 
    // wait for the RF environment to settle, and rebuild from scratch.
    for (int session = 0; session < 2; session++) {
        
        if (session > 0) {
            LOG_DBG("--- Initiating Costly Recovery (Session Attempt %d/2) ---", session + 1);
            k_msleep(1000); // 1-second physical delay to let Router/RF clear
        }

        mqtt_client_init(&client_ctx);
        k_sem_reset(&mqtt_conn_sem);
        k_sem_reset(&mqtt_pub_sem);

        broker.sin_family = AF_INET;
        broker.sin_port = htons(BROKER_PORT);
        zsock_inet_pton(AF_INET, BROKER_ADDR, &broker.sin_addr);

        client_ctx.broker = &broker;
        client_ctx.evt_cb = mqtt_evt_handler;
        client_ctx.client_id.utf8 = (uint8_t *)"esp32c6_sensor";
        client_ctx.client_id.size = strlen("esp32c6_sensor");
        password.utf8 = (uint8_t *)CONFIG_LPS_MQTT_BROKER_PASSWORD;
        password.size = strlen(CONFIG_LPS_MQTT_BROKER_PASSWORD);
        client_ctx.password = &password;
        username.utf8 = (uint8_t *)CONFIG_LPS_MQTT_BROKER_USERNAME;
        username.size = strlen(CONFIG_LPS_MQTT_BROKER_USERNAME);
        client_ctx.user_name = &username;
        client_ctx.protocol_version = MQTT_VERSION_3_1_1;
        client_ctx.rx_buf = rx_buffer;
        client_ctx.rx_buf_size = sizeof(rx_buffer);
        client_ctx.tx_buf = tx_buffer;
        client_ctx.tx_buf_size = sizeof(tx_buffer);
        client_ctx.transport.type = MQTT_TRANSPORT_NON_SECURE;

        // INNER LOOP: specifically mitigates the -22 EINVAL local OS race condition
        int err = -1;
        for (int attempts = 0; attempts < 3; attempts++) {
            LOG_DBG("Connecting to MQTT broker (Attempt %d/3)...", attempts + 1);
            err = mqtt_connect(&client_ctx);
            
            if (err == 0) {
                break; 
            }

            LOG_DBG("Connection failed: %d. Backing off...", err);
            k_msleep(500); // 500ms guarantees Zephyr's internal IPv4 tables are up
        }

        if (err != 0) {
            LOG_DBG("Session %d: Failed to connect.", session + 1);
            continue; // Trigger the Master Recovery Loop
        }

        fds[0].fd = client_ctx.transport.tcp.sock;
        fds[0].events = ZSOCK_POLLIN;
        
        // Wait for connection ACK
        bool connected = false;
        for (int i = 0; i < 50; i++) { 
            if (zsock_poll(fds, 1, 100) > 0) {
                mqtt_input(&client_ctx);
            }
            if (k_sem_take(&mqtt_conn_sem, K_NO_WAIT) == 0) {
                connected = true;
                break;
            }
        }

        if (!connected) {
            LOG_DBG("Session %d: Timeout waiting for CONNACK.", session + 1);
            mqtt_disconnect(&client_ctx, NULL); // Safely close the orphaned socket
            continue; // Trigger the Master Recovery Loop
        }

        LOG_DBG("Publishing data...");

	uint8_t is_dup = (session > 0) ? 1 : 0;
	
        if (publish_sensor_data(sensor_data->hp_wake_count, sensor_data->temp_c_x10, sensor_data->rh_x10, current_msg_id, is_dup) != 0) {
            LOG_DBG("Session %d: Failed to enqueue publish.", session + 1);
            mqtt_disconnect(&client_ctx, NULL);
            continue; 
        }

        // Wait for publish ACK
        bool published = false;
        for (int i = 0; i < 50; i++) { 
            if (zsock_poll(fds, 1, 100) > 0) {
                mqtt_input(&client_ctx);
            }
            if (k_sem_take(&mqtt_pub_sem, K_NO_WAIT) == 0) {
                published = true;
                break;
            }
        }

        if (!published) {
            LOG_DBG("Session %d: Timed out waiting for PUBACK. Network loss suspected.", session + 1);
            mqtt_disconnect(&client_ctx, NULL);
            continue; // Trigger the Master Recovery Loop!
        }

        // If we reach here, the packet is cryptographically verified on the broker.
        successful_publish = true;
        mqtt_disconnect(&client_ctx, NULL);
        break; // Break completely out of the Master Session loop
    }

    // Only if BOTH sessions completely failed do we drop the nuclear bomb
    if (!successful_publish) {
        LOG_DBG("Fatal: Exhausted all recovery attempts. Invalidating cache.");
        lps_wifi_invalidate_dhcp_cache();
    }

    return successful_publish;
}

bool lps_send_update(lp_to_hp_shared_data_t *data) {
    sensor_data = data;
    bool successful_publish = false;
    
    if (lps_wifi_prepare_connection()) {
        // Wi-Fi and IP routing are physically verified. Safe to run.
        successful_publish = send_mqtt_update();
    } else {
        // Wi-Fi failed. Skip MQTT, invalidate caches, and tear down immediately.
        LOG_DBG("Skipping MQTT publish due to Wi-Fi failure.");
        lps_wifi_invalidate_dhcp_cache();
    }
    
    lps_wifi_teardown_connection();

    k_msleep(50);

    return successful_publish;
}
```

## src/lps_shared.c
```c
#include "lps_shared.h"

void get_device_id(char *id_buffer, size_t buffer_size)
{
    struct net_if *iface = net_if_get_default();
    struct net_linkaddr *link_addr = net_if_get_link_addr(iface);

#if defined(CONFIG_LPS_TRANSPORT_WIFI_MQTT)    
    if (link_addr) {
        snprintf(id_buffer, buffer_size, "lps_%02x%02x%02x",
                 link_addr->addr[3], link_addr->addr[4], link_addr->addr[5]);
    }
#elif defined(CONFIG_LPS_TRANSPORT_THREAD_MQTTSN)     
    if (link_addr) {
        snprintf(id_buffer, buffer_size, "lps_%02x%02x%02x%02x",
                 link_addr->addr[4], link_addr->addr[5],
		 link_addr->addr[6], link_addr->addr[7]);
    }
#endif    
    else {
        snprintf(id_buffer, buffer_size, "unknown_device");
    }
}

void get_json_message(char *json_message_buffer, size_t buffer_size,
		      char* device_id, volatile lp_to_hp_shared_data_t *data)
{
    snprintf(json_message_buffer, buffer_size, 
             "{\"id\": \"%s\", \"seq\": %d, \"uptime\": %d, \"temperature\": %s%d.%d, \"humidity\": %d.%d}", 
             device_id,
	     data->hp_wake_count,
	     data->lp_wake_count,
             (data->temp_c_x10 < 0) ? "-" : "",               /* Explicitly add negative sign if needed */
             abs(data->temp_c_x10) / 10,                      /* Absolute value for the whole number portion */
             abs(data->temp_c_x10) % 10,                      /* Absolute value for the decimal portion */
             (data->rh_x10) / 10, abs((data->rh_x10) % 10));  /* Humidity is never negative, so it remains unchanged */
}

void get_topic(char *topic_buffer, size_t topic_buffer_size, char *device_id)
{
    snprintf(topic_buffer, topic_buffer_size, "sensors/%s/env", device_id);
}
```
